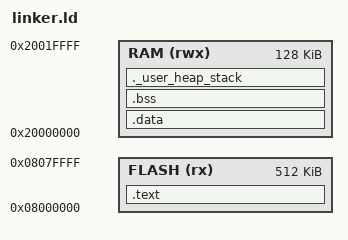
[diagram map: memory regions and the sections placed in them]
/* STM32F411 Bare-Metal Linker Script */

MEMORY
{
  FLASH (rx)  : ORIGIN = 0x08000000, LENGTH = 512K
  RAM   (rwx) : ORIGIN = 0x20000000, LENGTH = 128K
}

SECTIONS
{
  .text :
  {
    _stext = .;
    KEEP(*(.isr_vector))
    *(.text*)
    *(.rodata*)
    _etext = .;
  } > FLASH

  .data : AT (ADDR(.text) + SIZEOF(.text))
  {
    _sdata = .;
    *(.data*)
    _edata = .;
  } > RAM
  _sidata = LOADADDR(.data);

  .bss :
  {
    _sbss = .;
    *(.bss*)
    *(COMMON)
    _ebss = .;
  } > RAM

  ._user_heap_stack :
  {
    . = ALIGN(8);
    _end = .;
    PROVIDE(end = .);
  } > RAM
}

